VERSION ""

NS_ :

BS_:

BU_:

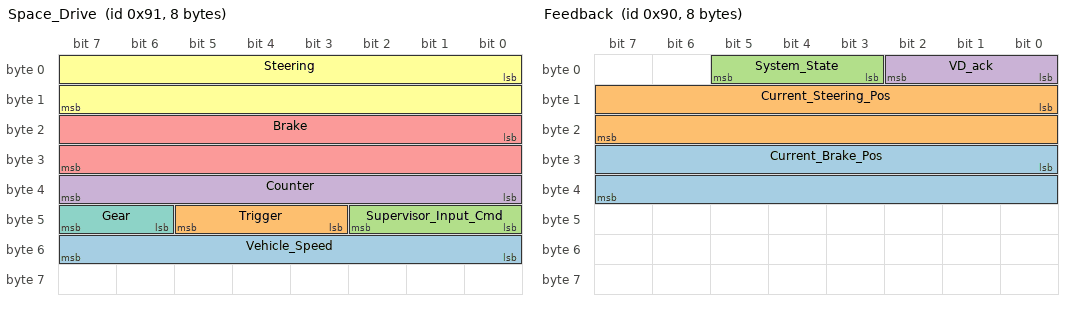
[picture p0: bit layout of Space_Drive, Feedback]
BO_ 145 Space_Drive: 8 Vector__XXX
 SG_ Vehicle_Speed : 48|8@1+ (1,0) [0|255] "" Vector__XXX
 SG_ Trigger : 43|3@1+ (1,0) [0|7] "" Vector__XXX
 SG_ Supervisor_Input_Cmd : 40|3@1+ (1,0) [0|7] "" Vector__XXX
 SG_ Counter : 32|8@1+ (1,0) [0|255] "" Vector__XXX
 SG_ Brake : 16|16@1+ (1,0) [0|65535] "" Vector__XXX
 SG_ Steering : 0|16@1+ (1,0) [0|65535] "" Vector__XXX
 SG_ Gear : 46|2@1+ (1,0) [0|0] "" Vector__XXX

BO_ 144 Feedback: 8 Vector__XXX
 SG_ Current_Brake_Pos : 24|16@1+ (1,0) [0|65535] "" Vector__XXX
 SG_ Current_Steering_Pos : 8|16@1+ (1,0) [0|65535] "" Vector__XXX
 SG_ System_State : 3|3@1+ (1,0) [0|7] "" Vector__XXX
 SG_ VD_ack : 0|3@1+ (1,0) [0|7] "" Vector__XXX

BA_DEF_  "BusType" STRING ;
BA_DEF_DEF_  "BusType" "";
BA_ "BusType" "CAN";
